# CY8C5888LTI_LP097 register map
File version: 0.1
Registers are 8-bit, read-write, no defined reset value unless marked. A register's access mark holds for its fields unless they carry their own. Offsets are from the block's base; [hi:lo] are bit positions; 'fields as' and 'values as' point back to an identical list.

## UART_HC12 — UART
Base 0x00000000
0x40006448 TX_UART_HC12_TX_DATA — TX Data Register
0x4000652B RX_UART_HC12_RX_ADDRESS1 — RX Address1 Register
0x4000653B RX_UART_HC12_RX_ADDRESS2 — RX Address2 Register
0x4000654B RX_UART_HC12_RX_DATA — RX Data Register
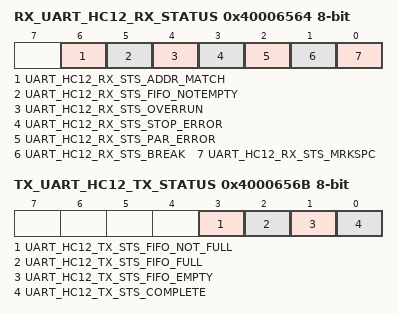
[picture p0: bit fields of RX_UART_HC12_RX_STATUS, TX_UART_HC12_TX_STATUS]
0x40006564 RX_UART_HC12_RX_STATUS — RX status register
  [6] UART_HC12_RX_STS_ADDR_MATCH ro, [5] UART_HC12_RX_STS_FIFO_NOTEMPTY ro, [4] UART_HC12_RX_STS_OVERRUN ro, [3] UART_HC12_RX_STS_STOP_ERROR ro, [2] UART_HC12_RX_STS_PAR_ERROR ro, [1] UART_HC12_RX_STS_BREAK ro, [0] UART_HC12_RX_STS_MRKSPC ro
0x4000656B TX_UART_HC12_TX_STATUS — TX status register
  [3] UART_HC12_TX_STS_FIFO_NOT_FULL ro, [2] UART_HC12_TX_STS_FIFO_FULL ro, [1] UART_HC12_TX_STS_FIFO_EMPTY ro, [0] UART_HC12_TX_STS_COMPLETE ro

## UART_GPS — UART
Base 0x00000000
0x40006420 RX_UART_GPS_RX_ADDRESS1 — RX Address1 Register
0x40006430 RX_UART_GPS_RX_ADDRESS2 — RX Address2 Register
0x40006440 RX_UART_GPS_RX_DATA — RX Data Register
0x4000644A TX_UART_GPS_TX_DATA — TX Data Register
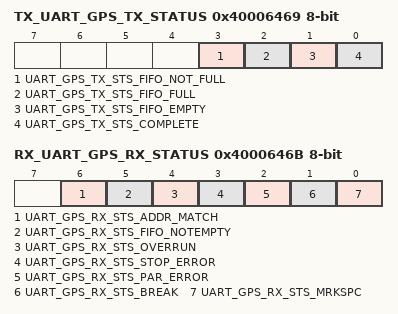
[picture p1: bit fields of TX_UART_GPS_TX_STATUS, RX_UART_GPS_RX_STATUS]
0x40006469 TX_UART_GPS_TX_STATUS — TX status register
  [3] UART_GPS_TX_STS_FIFO_NOT_FULL ro, [2] UART_GPS_TX_STS_FIFO_FULL ro, [1] UART_GPS_TX_STS_FIFO_EMPTY ro, [0] UART_GPS_TX_STS_COMPLETE ro
0x4000646B RX_UART_GPS_RX_STATUS — RX status register
  [6] UART_GPS_RX_STS_ADDR_MATCH ro, [5] UART_GPS_RX_STS_FIFO_NOTEMPTY ro, [4] UART_GPS_RX_STS_OVERRUN ro, [3] UART_GPS_RX_STS_STOP_ERROR ro, [2] UART_GPS_RX_STS_PAR_ERROR ro, [1] UART_GPS_RX_STS_BREAK ro, [0] UART_GPS_RX_STS_MRKSPC ro

## Aileron
Base 0x00000000
0x40006524 Aileron_COMPARE_1 16-bit — UDB.D0 - Assigned Compare1 Value
0x40006534 Aileron_COMPARE_2 16-bit — UDB.D1 - Assigned Compare2 Value
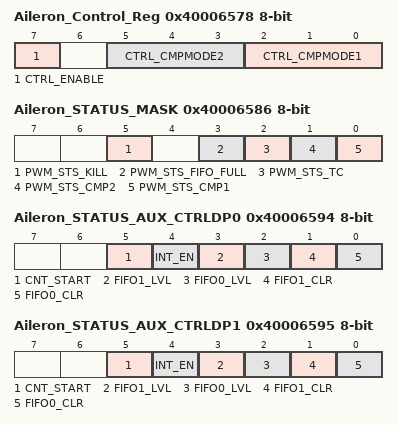
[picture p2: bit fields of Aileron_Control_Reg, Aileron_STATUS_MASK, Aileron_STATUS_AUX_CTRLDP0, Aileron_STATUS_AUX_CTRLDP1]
0x40006578 Aileron_Control_Reg — UDB Control Register - Assigned Control Register Value
  [7] CTRL_ENABLE — Enable the PWM
  [5:3] CTRL_CMPMODE2 — Compare mode 2
  [2:0] CTRL_CMPMODE1 — Compare mode 1
0x40006586 Aileron_STATUS_MASK — UDB Status bits Interrupt Mask Enable Register
  [5] PWM_STS_KILL ro — Enables the Interrupt on Kill
  [3] PWM_STS_FIFO_FULL ro — FIFO Full Status Mask
  [2] PWM_STS_TC ro — Enables the Interrupt on Terminal Count
  [1] PWM_STS_CMP2 ro — Enables the Interrupt on Compare 2
  [0] PWM_STS_CMP1 ro — Enables the Interrupt on Compare 1
0x40006594 Aileron_STATUS_AUX_CTRLDP0 — UDB Auxilliary Control Register
  [5] CNT_START — FIFO0 clear
    0=E_CNT_START0 (Disable counter); 1=E_CNT_START1 (Enable counter)
  [4] INT_EN
    0=E_INT_EN0 (Interrupt disabled); 1=E_INT_EN1 (Interrupt enabled)
  [3] FIFO1_LVL — FIFO level
    0=E_FIFO_LVL_0 (FIFO LVL: input mode: FIFO not full; output mode: FIFO not empty); 1=E_FIFO_LVL_1 (FIFO LVL: input mode: FIFO at least 1/2 empty; output mode: FIFO at least 1/2 full)
  [2] FIFO0_LVL — FIFO level
    values as FIFO1_LVL
  [1] FIFO1_CLR — FIFO1 clear
    0=E_FIFO_CLR_0 (Normal FIFO operation); 1=E_FIFO_CLR_1 (Clear FIFO state)
  [0] FIFO0_CLR — FIFO0 clear
    values as FIFO1_CLR
0x40006595 Aileron_STATUS_AUX_CTRLDP1 — UDB Auxilliary Control Register
  fields as Aileron_STATUS_AUX_CTRLDP0

## Stabilizer
Base 0x00000000
0x40006426 Stabilizer_COMPARE_1 16-bit — UDB.D0 - Assigned Compare1 Value
0x40006436 Stabilizer_COMPARE_2 16-bit — UDB.D1 - Assigned Compare2 Value
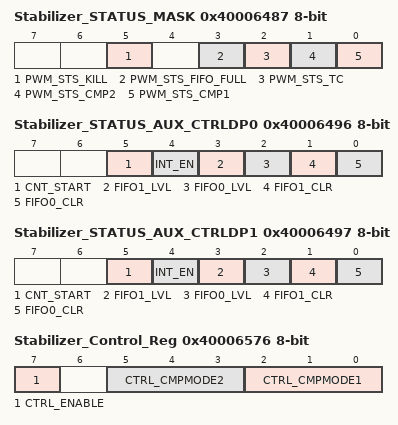
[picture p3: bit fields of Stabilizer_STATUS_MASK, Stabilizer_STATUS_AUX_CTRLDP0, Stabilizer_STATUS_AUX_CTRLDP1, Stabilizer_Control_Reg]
0x40006487 Stabilizer_STATUS_MASK — UDB Status bits Interrupt Mask Enable Register
  [5] PWM_STS_KILL ro — Enables the Interrupt on Kill
  [3] PWM_STS_FIFO_FULL ro — FIFO Full Status Mask
  [2] PWM_STS_TC ro — Enables the Interrupt on Terminal Count
  [1] PWM_STS_CMP2 ro — Enables the Interrupt on Compare 2
  [0] PWM_STS_CMP1 ro — Enables the Interrupt on Compare 1
0x40006496 Stabilizer_STATUS_AUX_CTRLDP0 — UDB Auxilliary Control Register
  [5] CNT_START — FIFO0 clear
    0=E_CNT_START0 (Disable counter); 1=E_CNT_START1 (Enable counter)
  [4] INT_EN
    0=E_INT_EN0 (Interrupt disabled); 1=E_INT_EN1 (Interrupt enabled)
  [3] FIFO1_LVL — FIFO level
    0=E_FIFO_LVL_0 (FIFO LVL: input mode: FIFO not full; output mode: FIFO not empty); 1=E_FIFO_LVL_1 (FIFO LVL: input mode: FIFO at least 1/2 empty; output mode: FIFO at least 1/2 full)
  [2] FIFO0_LVL — FIFO level
    values as FIFO1_LVL
  [1] FIFO1_CLR — FIFO1 clear
    0=E_FIFO_CLR_0 (Normal FIFO operation); 1=E_FIFO_CLR_1 (Clear FIFO state)
  [0] FIFO0_CLR — FIFO0 clear
    values as FIFO1_CLR
0x40006497 Stabilizer_STATUS_AUX_CTRLDP1 — UDB Auxilliary Control Register
  fields as Stabilizer_STATUS_AUX_CTRLDP0
0x40006576 Stabilizer_Control_Reg — UDB Control Register - Assigned Control Register Value
  [7] CTRL_ENABLE — Enable the PWM
  [5:3] CTRL_CMPMODE2 — Compare mode 2
  [2:0] CTRL_CMPMODE1 — Compare mode 1
